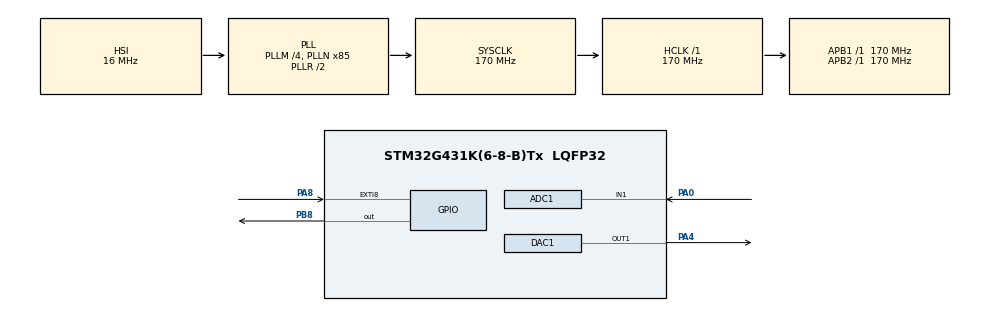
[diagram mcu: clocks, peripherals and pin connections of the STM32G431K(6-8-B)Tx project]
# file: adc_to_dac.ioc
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ADC1.Channel-0\#ChannelRegularConversion=ADC_CHANNEL_1
ADC1.DMAContinuousRequests=ENABLE
ADC1.ExternalTrigConv=ADC_EXTERNALTRIG_T7_TRGO
ADC1.NbrOfConversionFlag=1
ADC1.OffsetNumber-0\#ChannelRegularConversion=ADC_OFFSET_NONE
ADC1.Rank-0\#ChannelRegularConversion=1
ADC1.SamplingTime-0\#ChannelRegularConversion=ADC_SAMPLETIME_2CYCLES_5
ADC1.master=1
DAC1.DAC_Trigger_OUT1-DAC_OUT1=DAC_TRIGGER_T7_TRGO
Dma.ADC1.0.Direction=DMA_PERIPH_TO_MEMORY
Dma.ADC1.0.EventEnable=DISABLE
Dma.ADC1.0.Instance=DMA1_Channel1
Dma.ADC1.0.MemDataAlignment=DMA_MDATAALIGN_WORD
Dma.ADC1.0.MemInc=DMA_MINC_ENABLE
Dma.ADC1.0.Mode=DMA_CIRCULAR
Dma.ADC1.0.PeriphDataAlignment=DMA_PDATAALIGN_HALFWORD
Dma.ADC1.0.PeriphInc=DMA_PINC_DISABLE
Dma.ADC1.0.Polarity=HAL_DMAMUX_REQ_GEN_RISING
Dma.ADC1.0.Priority=DMA_PRIORITY_LOW
Dma.ADC1.0.RequestNumber=1
Dma.ADC1.0.SignalID=NONE
Dma.ADC1.0.SyncEnable=DISABLE
Dma.ADC1.0.SyncPolarity=HAL_DMAMUX_SYNC_NO_EVENT
Dma.ADC1.0.SyncRequestNumber=1
Dma.ADC1.0.SyncSignalID=NONE
Dma.DAC1_CH1.1.Direction=DMA_MEMORY_TO_PERIPH
Dma.DAC1_CH1.1.EventEnable=DISABLE
Dma.DAC1_CH1.1.Instance=DMA1_Channel2
Dma.DAC1_CH1.1.MemDataAlignment=DMA_MDATAALIGN_WORD
Dma.DAC1_CH1.1.MemInc=DMA_MINC_ENABLE
Dma.DAC1_CH1.1.Mode=DMA_CIRCULAR
Dma.DAC1_CH1.1.PeriphDataAlignment=DMA_PDATAALIGN_WORD
Dma.DAC1_CH1.1.PeriphInc=DMA_PINC_DISABLE
Dma.DAC1_CH1.1.Polarity=HAL_DMAMUX_REQ_GEN_RISING
Dma.DAC1_CH1.1.Priority=DMA_PRIORITY_LOW
Dma.DAC1_CH1.1.RequestNumber=1
Dma.DAC1_CH1.1.SignalID=NONE
Dma.DAC1_CH1.1.SyncEnable=DISABLE
Dma.DAC1_CH1.1.SyncPolarity=HAL_DMAMUX_SYNC_NO_EVENT
Dma.DAC1_CH1.1.SyncRequestNumber=1
Dma.DAC1_CH1.1.SyncSignalID=NONE
Dma.Request0=ADC1
Dma.Request1=DAC1_CH1
Mcu.Family=STM32G4
Mcu.Name=STM32G431K(6-8-B)Tx
Mcu.Package=LQFP32
NUCLEO-G431KB.Bsp_Common_DEMO=true
NUCLEO-G431KB.LD2=true
NUCLEO-G431KB.VCP=true
NVIC.DMA1_Channel1_IRQn=true\:0\:0\:false\:false\:true\:false\:true\:true
NVIC.DMA1_Channel2_IRQn=true\:0\:0\:false\:false\:true\:false\:true\:true
NVIC.EXTI9_5_IRQn=true\:0\:0\:false\:false\:true\:true\:true\:true
NVIC.PriorityGroup=NVIC_PRIORITYGROUP_4
NVIC.TIM2_IRQn=true\:0\:0\:false\:false\:true\:true\:true\:true
NVIC.TIM7_IRQn=true\:0\:0\:false\:false\:true\:true\:true\:true
PA0.Mode=IN1-Single-Ended
PA0.Signal=ADC1_IN1
PA13.GPIO_Label=T_SWDIO
PA13.Signal=SYS_JTMS-SWDIO
PA14.GPIO_Label=T_SWCLK
PA14.Signal=SYS_JTCK-SWCLK
PA2.Signal=USART2_TX
PA3.Signal=USART2_RX
PA4.Signal=COMP_DAC11_group
PA8.Signal=GPXTI8
PB3.GPIO_Label=T_SWO
PB3.Signal=SYS_JTDO-SWO
PB8-BOOT0.Signal=GPIO_Output
ProjectManager.HeapSize=0x200
ProjectManager.StackSize=0x400
ProjectManager.TargetToolchain=STM32CubeIDE
RCC.ADC12Freq_Value=170000000
RCC.AHBFreq_Value=170000000
RCC.APB1Freq_Value=170000000
RCC.APB1TimFreq_Value=170000000
RCC.APB2Freq_Value=170000000
RCC.APB2TimFreq_Value=170000000
RCC.CortexFreq_Value=170000000
RCC.EXTERNAL_CLOCK_VALUE=12288000
RCC.HCLKFreq_Value=170000000
RCC.HSE_VALUE=8000000
RCC.HSI48_VALUE=48000000
RCC.HSI_VALUE=16000000
RCC.LSE_VALUE=32768
RCC.PLLM=RCC_PLLM_DIV4
RCC.PLLN=85
RCC.SYSCLKFreq_VALUE=170000000
RCC.SYSCLKSource=RCC_SYSCLKSOURCE_PLLCLK
RCC.USBFreq_Value=170000000
RCC.VCOOutputFreq_Value=340000000
SH.COMP_DAC11_group.0=DAC1_OUT1,DAC_OUT1
TIM2.ClockDivision=TIM_CLOCKDIVISION_DIV2
TIM2.PeriodNoDither=4899
TIM2.Prescaler=109
TIM7.PeriodNoDither=10-1
TIM7.Prescaler=17-1
TIM7.TIM_MasterOutputTrigger=TIM_TRGO_UPDATE
VP_NUCLEO-G431KB_VS_BSP_COMMON.Mode=COMMON
VP_SYS_VS_DBSignals.Mode=DisableDeadBatterySignals
VP_TIM2_VS_ClockSourceINT.Mode=Internal
VP_TIM7_VS_ClockSourceINT.Mode=Enable_Timer
board=NUCLEO-G431KB

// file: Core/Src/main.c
/* USER CODE BEGIN Header */
/**
  ******************************************************************************
  * @file           : main.c
  * @brief          : Main program body
  ******************************************************************************
  * @attention
  *
  * Copyright (c) 2025 STMicroelectronics.
  * All rights reserved.
  *
  * This software is licensed under terms that can be found in the LICENSE file
  * in the root directory of this software component.
  * If no LICENSE file comes with this software, it is provided AS-IS.
  *
  ******************************************************************************
  */
/* USER CODE END Header */
#include "main.h"
#include "adc.h"
#include "dac.h"
#include "dma.h"
#include "tim.h"
#include "gpio.h"

/* USER CODE BEGIN PD */
// Size of the ADC/DAC buffers
#define		N			512
#define		halfN		256

/* USER CODE END PD */

COM_InitTypeDef BspCOMInit;

/* USER CODE BEGIN PV */
// ADC and DAC buffers
uint32_t 	adc_buffer[N];
uint32_t 	dac_buffer[N];

/* USER CODE END PV */

void SystemClock_Config(void);

int main(void)
{

  /* MCU Configuration--------------------------------------------------------*/

  /* Reset of all peripherals, Initializes the Flash interface and the Systick. */
  HAL_Init();

  /* Configure the system clock */
  SystemClock_Config();

  /* Initialize all configured peripherals */
  MX_GPIO_Init();
  MX_DMA_Init();
  MX_ADC1_Init();
  MX_TIM2_Init();
  MX_DAC1_Init();
  MX_TIM7_Init();
  /* USER CODE BEGIN 2 */

  // Initialization of ADC and DAC
  HAL_ADC_Start_DMA(&hadc1, adc_buffer, N);
  HAL_DAC_Start_DMA(&hdac1, DAC_CHANNEL_1, dac_buffer, N, DAC_ALIGN_12B_R);
  HAL_TIM_Base_Start(&htim7);

  /* USER CODE END 2 */

  /* Initialize leds */
  BSP_LED_Init(LED_GREEN);

  /* Initialize COM1 port (115200, 8 bits (7-bit data + 1 stop bit), no parity */
  BspCOMInit.BaudRate   = 115200;
  BspCOMInit.WordLength = COM_WORDLENGTH_8B;
  BspCOMInit.StopBits   = COM_STOPBITS_1;
  BspCOMInit.Parity     = COM_PARITY_NONE;
  BspCOMInit.HwFlowCtl  = COM_HWCONTROL_NONE;
  if (BSP_COM_Init(COM1, &BspCOMInit) != BSP_ERROR_NONE)
  {
    Error_Handler();
  }

  /* USER CODE BEGIN BSP */

  /* -- Sample board code to send message over COM1 port ---- */
  printf("Welcome to STM32 world !\n\r");

  /* -- Sample board code to switch on leds ---- */
  BSP_LED_On(LED_GREEN);

  /* USER CODE END BSP */

  /* Infinite loop */
  /* USER CODE BEGIN WHILE */
  while (1)
  {

/* -- Sample board code to toggle leds ---- */
       BSP_LED_Toggle(LED_GREEN);

    /* USER CODE END WHILE */

  }
}

void SystemClock_Config(void)
{
  RCC_OscInitTypeDef RCC_OscInitStruct = {0};
  RCC_ClkInitTypeDef RCC_ClkInitStruct = {0};

  /** Configure the main internal regulator output voltage
  */
  HAL_PWREx_ControlVoltageScaling(PWR_REGULATOR_VOLTAGE_SCALE1_BOOST);

  /** Initializes the RCC Oscillators according to the specified parameters
  * in the RCC_OscInitTypeDef structure.
  */
  RCC_OscInitStruct.OscillatorType = RCC_OSCILLATORTYPE_HSI;
  RCC_OscInitStruct.HSIState = RCC_HSI_ON;
  RCC_OscInitStruct.HSICalibrationValue = RCC_HSICALIBRATION_DEFAULT;
  RCC_OscInitStruct.PLL.PLLState = RCC_PLL_ON;
  RCC_OscInitStruct.PLL.PLLSource = RCC_PLLSOURCE_HSI;
  RCC_OscInitStruct.PLL.PLLM = RCC_PLLM_DIV4;
  RCC_OscInitStruct.PLL.PLLN = 85;
  RCC_OscInitStruct.PLL.PLLP = RCC_PLLP_DIV2;
  RCC_OscInitStruct.PLL.PLLQ = RCC_PLLQ_DIV2;
  RCC_OscInitStruct.PLL.PLLR = RCC_PLLR_DIV2;
  if (HAL_RCC_OscConfig(&RCC_OscInitStruct) != HAL_OK)
  {
    Error_Handler();
  }

  /** Initializes the CPU, AHB and APB buses clocks
  */
  RCC_ClkInitStruct.ClockType = RCC_CLOCKTYPE_HCLK|RCC_CLOCKTYPE_SYSCLK
                              |RCC_CLOCKTYPE_PCLK1|RCC_CLOCKTYPE_PCLK2;
  RCC_ClkInitStruct.SYSCLKSource = RCC_SYSCLKSOURCE_PLLCLK;
  RCC_ClkInitStruct.AHBCLKDivider = RCC_SYSCLK_DIV1;
  RCC_ClkInitStruct.APB1CLKDivider = RCC_HCLK_DIV1;
  RCC_ClkInitStruct.APB2CLKDivider = RCC_HCLK_DIV1;

  if (HAL_RCC_ClockConfig(&RCC_ClkInitStruct, FLASH_LATENCY_4) != HAL_OK)
  {
    Error_Handler();
  }
}

/* USER CODE BEGIN 4 */

// ISR for ADC and DAC conversion
void HAL_ADC_ConvHalfCpltCallback(ADC_HandleTypeDef* hadc){
	for(int n=0; n<halfN; n++){ dac_buffer[n] = adc_buffer[n] / 2; }
}

void HAL_ADC_ConvCpltCallback(ADC_HandleTypeDef* hadc){
	for(int n=halfN; n<N; n++){ dac_buffer[n] = adc_buffer[n]; }
}

/* USER CODE END 4 */

/* USER CODE BEGIN Header */
/**
  ******************************************************************************
  * @file           : main.c
  * @brief          : Main program body
  ******************************************************************************
  * @attention
  *
  * Copyright (c) 2025 STMicroelectronics.
  * All rights reserved.
  *
  * This software is licensed under terms that can be found in the LICENSE file
  * in the root directory of this software component.
  * If no LICENSE file comes with this software, it is provided AS-IS.
  *
  ******************************************************************************
  */
/* USER CODE END Header */

void Error_Handler(void)
{
  __disable_irq();
  while (1)
  {
  }
}
